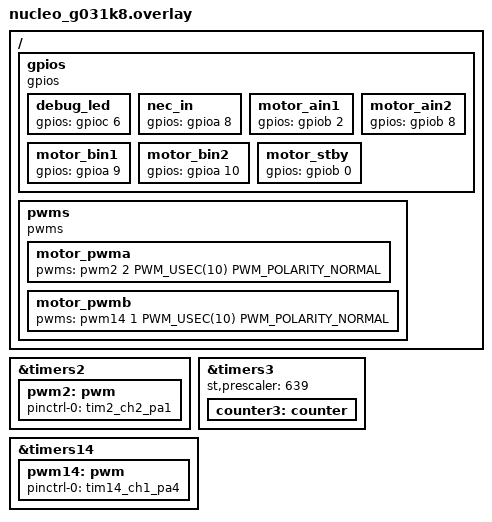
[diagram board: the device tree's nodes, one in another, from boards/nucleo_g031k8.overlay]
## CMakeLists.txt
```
cmake_minimum_required(VERSION 3.20.0)

find_package(Zephyr REQUIRED HINTS $ENV{ZEPHYR_BASE})

project(mort)

set(MORT_SOURCES
    src/main.c
    src/driver/led.c
    src/driver/nec.c
    src/driver/tb6612fng_dc.c
    src/hal/counter.c
    src/hal/gpio.c
    src/hal/pwm.c
    src/hal/detail/dt.c
    src/task/app.c
    src/util/debug.c)

target_include_directories(app PRIVATE src)
target_sources(app PRIVATE ${MORT_SOURCES})
```

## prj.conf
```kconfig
CONFIG_SERIAL=y
CONFIG_GPIO=y
CONFIG_COUNTER=y
CONFIG_COUNTER_TIMER_STM32=y
CONFIG_PWM=y
CONFIG_PWM_STM32=y

CONFIG_MAIN_STACK_SIZE=640
CONFIG_IDLE_STACK_SIZE=200
CONFIG_ISR_STACK_SIZE=512

CONFIG_UART_INTERRUPT_DRIVEN=y
# CONFIG_PM=y
# CONFIG_PM_DEVICE=y

CONFIG_CONSOLE=y
CONFIG_UART_CONSOLE=y

CONFIG_STD_C17=y
```

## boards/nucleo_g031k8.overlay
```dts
&timers2 {
    status = "okay";

    pwm2: pwm {
        status = "okay";
        pinctrl-0 = <&tim2_ch2_pa1>;
        pinctrl-names = "default";
    };
};

&timers3 {
    status = "okay";
    st,prescaler = <639>; // Clock at 64 MHz, 10us period

    counter3: counter {
        status = "okay";
    };
};

&timers14 {
    status = "okay";

    pwm14: pwm {
        status = "okay";
        pinctrl-0 = <&tim14_ch1_pa4>;
        pinctrl-names = "default";
    };
};

/ {
    gpios: gpios {
        compatible = "gpios";

        debug_led: debug_led {
            gpios = <&gpioc 6 GPIO_ACTIVE_HIGH>;
        };

        nec_in: nec_in {
            gpios = <&gpioa 8 GPIO_ACTIVE_HIGH>;
        };

        motor_ain1: motor_ain1 {
            gpios = <&gpiob 2 GPIO_ACTIVE_HIGH>;
        };

        motor_ain2: motor_ain2 {
            gpios = <&gpiob 8 GPIO_ACTIVE_HIGH>;
        };

        motor_bin1: motor_bin1 {
            gpios = <&gpioa 9 GPIO_ACTIVE_HIGH>;
        };

        motor_bin2: motor_bin2 {
            gpios = <&gpioa 10 GPIO_ACTIVE_HIGH>;
        };

        motor_stby: motor_stby {
            gpios = <&gpiob 0 GPIO_ACTIVE_HIGH>;
        };
    };

    pwms: pwms {
        compatible = "pwms";

        motor_pwma: motor_pwma {
            pwms = <&pwm2 2 PWM_USEC(10) PWM_POLARITY_NORMAL>;
        };

        motor_pwmb: motor_pwmb {
            pwms = <&pwm14 1 PWM_USEC(10) PWM_POLARITY_NORMAL>;
        };
    };

    /delete-node/ aliases;
    /delete-node/ leds;
};
```

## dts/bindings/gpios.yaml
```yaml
description: Miscellaneous GPIO pins for MORT.

compatible: "gpios"

child-binding:
  description: GPIO child nodes.
  properties:
    gpios:
     type: phandle-array
     required: true
```

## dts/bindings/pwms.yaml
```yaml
description: PWM nodes for use by MORT.

compatible: "pwms"

child-binding:
  description: PWM child nodes.
  properties:
    pwms:
      type: phandle-array
      required: true
      description: |
        Reference to a PWM instance.

        <phandle channel period(ns) flags>
```

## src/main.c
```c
#include "hal/counter.h"
#include "hal/gpio.h"
#include "hal/pwm.h"
#include "task/app.h"
#include "util/debug.h"

int main(void)
{
    int ec = 0;

    ec = mort_gpio_init();
    MORT_ASSERT_MSG(ec == 0, "Failed to initialize the GPIO");

    ec = mort_counter_init();
    MORT_ASSERT_MSG(ec == 0, "Failed to initialize the counter");

    ec = mort_pwm_init(MORT_PWM_CH_MOTORR);
    MORT_ASSERT_MSG(ec == 0, "Failed to initialize the MOTORR PWM");

    ec = mort_pwm_init(MORT_PWM_CH_MOTORL);
    MORT_ASSERT_MSG(ec == 0, "Failed to initialize the MOTORL PWM");

    ec = mort_app_task_init();
    MORT_ASSERT_MSG(ec == 0, "Failed to initialize the app task");

    mort_app_task_run();

    // NOTE(Caleb): We should never get to this point
    return 0;
}
```

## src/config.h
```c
#pragma once

#include <zephyr/kernel.h>

#define __MORT_IDLE_TASK_PRIO    CONFIG_NUM_COOP_PRIORITIES
```

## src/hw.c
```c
#include "hw.h"

#include <avr/interrupt.h>

void hw_init(void) {
    // Initialize IO pins
    io_configure(
        MORT_DEBUG_LED, (io_config){.direction = IO_DIRECTION_OUTPUT, .initial_level = IO_HIGH});

    // Initialize the USART
    usart_init(MORT_USART, (usart_config){.baud_rate = USART_BAUD_57600, .echo_on_recv = true});

    // Enable interrupts
    sei();
}
```

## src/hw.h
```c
#ifndef _CALEBRJC_MORT_HW_H_
#define _CALEBRJC_MORT_HW_H_

#include <bsp/io.h>
#include <bsp/usart.h>

#define MORT_USART     BSP_USART0
#define MORT_DEBUG_LED BSP_PB5

/// @brief Initialize MCU hardware and BSP components for MORT.
void hw_init(void);

#endif  // _CALEBRJC_MORT_HW_H_
```
